# ESP32-P4 register map
Vendor: ESPRESSIF SYSTEMS (SHANGHAI) CO., LTD.; Series: ESP32 P-Series; File version: 3
CPU: RV32IMAFC r0p0, little endian, no MPU, FPU, 0 interrupt priority bits
Address unit: 32 bits
Registers are 32-bit, read-write, reset 0x0 unless marked. A register's access mark holds for its fields unless they carry their own. Offsets are from the block's base; [hi:lo] are bit positions; {n}, {i} and the like mark numbered series; <NAME> marks a mode.

## ISP (part 2 of 2) — ISP Peripheral
Base 0x500A1000
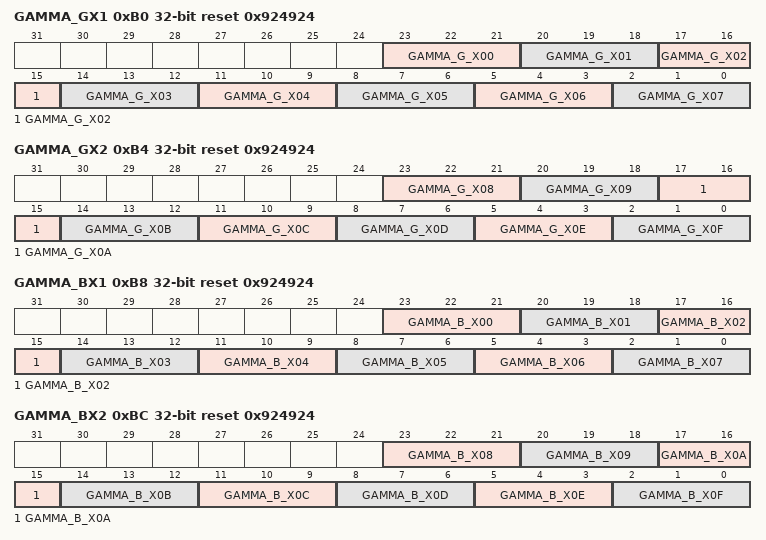
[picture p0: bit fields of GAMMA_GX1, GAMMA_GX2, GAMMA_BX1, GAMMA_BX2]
0xB0 GAMMA_GX1 reset 0x924924 — point of X-axis of g channel gamma curve register 1
  [23-3n:21-3n] GAMMA_G_X{n:02} (n=0..7) — this field configures the point {n} of X-axis of g channel gamma curve, it represents the power of the distance from the previous point
0xB4 GAMMA_GX2 reset 0x924924 — point of X-axis of g channel gamma curve register 2
  [23:21] GAMMA_G_X08 — this field configures the point 8 of X-axis of g channel gamma curve, it represents the power of the distance from the previous point
  [20:18] GAMMA_G_X09 — this field configures the point 9 of X-axis of g channel gamma curve, it represents the power of the distance from the previous point
  [17:15] GAMMA_G_X0A — this field configures the point 10 of X-axis of g channel gamma curve, it represents the power of the distance from the previous point
  [14:12] GAMMA_G_X0B — this field configures the point 11 of X-axis of g channel gamma curve, it represents the power of the distance from the previous point
  [11:9] GAMMA_G_X0C — this field configures the point 12 of X-axis of g channel gamma curve, it represents the power of the distance from the previous point
  [8:6] GAMMA_G_X0D — this field configures the point 13 of X-axis of g channel gamma curve, it represents the power of the distance from the previous point
  [5:3] GAMMA_G_X0E — this field configures the point 14 of X-axis of g channel gamma curve, it represents the power of the distance from the previous point
  [2:0] GAMMA_G_X0F — this field configures the point 15 of X-axis of g channel gamma curve, it represents the power of the distance from the previous point
0xB8 GAMMA_BX1 reset 0x924924 — point of X-axis of b channel gamma curve register 1
  [23-3n:21-3n] GAMMA_B_X{n:02} (n=0..7) — this field configures the point {n} of X-axis of b channel gamma curve, it represents the power of the distance from the previous point
0xBC GAMMA_BX2 reset 0x924924 — point of X-axis of b channel gamma curve register 2
  [23:21] GAMMA_B_X08 — this field configures the point 8 of X-axis of b channel gamma curve, it represents the power of the distance from the previous point
  [20:18] GAMMA_B_X09 — this field configures the point 9 of X-axis of b channel gamma curve, it represents the power of the distance from the previous point
  [17:15] GAMMA_B_X0A — this field configures the point 10 of X-axis of b channel gamma curve, it represents the power of the distance from the previous point
  [14:12] GAMMA_B_X0B — this field configures the point 11 of X-axis of b channel gamma curve, it represents the power of the distance from the previous point
  [11:9] GAMMA_B_X0C — this field configures the point 12 of X-axis of b channel gamma curve, it represents the power of the distance from the previous point
  [8:6] GAMMA_B_X0D — this field configures the point 13 of X-axis of b channel gamma curve, it represents the power of the distance from the previous point
  [5:3] GAMMA_B_X0E — this field configures the point 14 of X-axis of b channel gamma curve, it represents the power of the distance from the previous point
  [2:0] GAMMA_B_X0F — this field configures the point 15 of X-axis of b channel gamma curve, it represents the power of the distance from the previous point
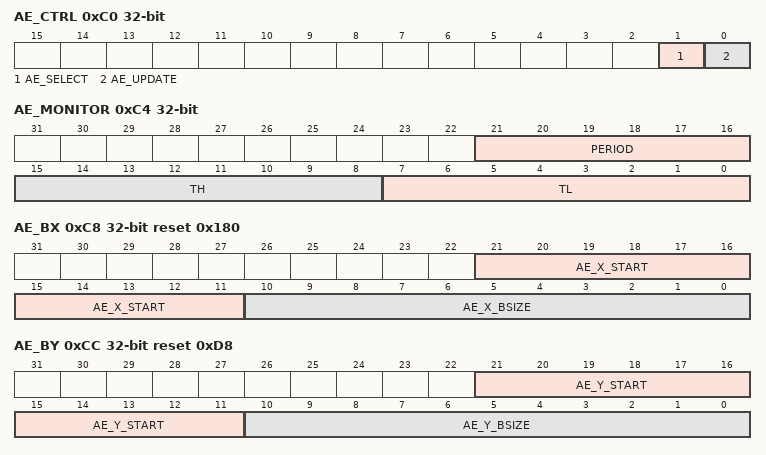
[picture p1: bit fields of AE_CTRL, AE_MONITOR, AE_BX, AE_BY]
0xC0 AE_CTRL access per field — ae control register
  [1] AE_SELECT rw — this field configures ae input data source, 0: data from median, 1: data from gama
  [0] AE_UPDATE wo — write 1 to this bit triggers one statistic event
0xC4 AE_MONITOR — ae monitor control register
  [21:16] PERIOD — this field cnfigures ae monitor frame period
  [15:8] TH — this field configures the higher lum threshold of ae monitor
  [7:0] TL — this field configures the lower lum threshold of ae monitor
0xC8 AE_BX reset 0x180 — ae window register in x-direction
  [21:11] AE_X_START — this field configures first block start x address
  [10:0] AE_X_BSIZE — this field configures every block x size
0xCC AE_BY reset 0xD8 — ae window register in y-direction
  [21:11] AE_Y_START — this field configures first block start y address
  [10:0] AE_Y_BSIZE — this field configures every block y size
0xD0 AE_WINPIXNUM reset 0x14400 — ae sub-window pix num register
  [16:0] AE_SUBWIN_PIXNUM — this field configures the pixel number of each sub win
0xD4 AE_WIN_RECIPROCAL — reciprocal of ae sub-window pixel number
  [19:0] AE_SUBWIN_RECIP — this field configures the reciprocal of each subwin_pixnum, 20bit fraction
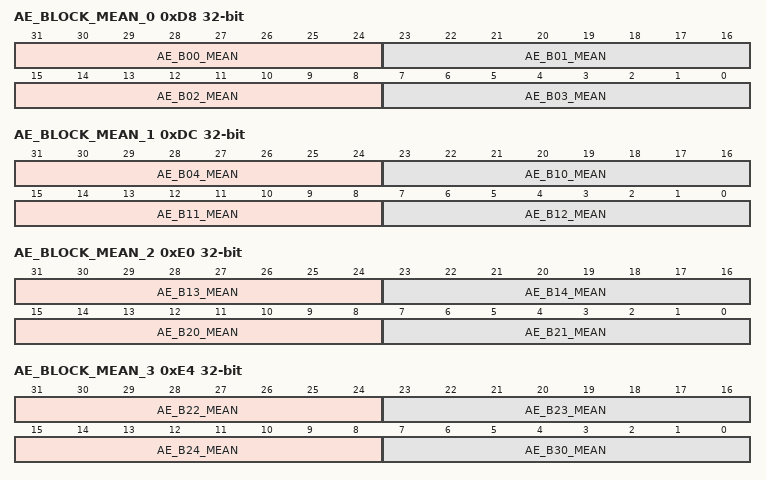
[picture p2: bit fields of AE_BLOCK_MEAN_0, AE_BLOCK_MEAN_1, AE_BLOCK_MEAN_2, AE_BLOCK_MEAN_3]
0xD8 AE_BLOCK_MEAN_0 ro — ae statistic result register 0
  [31-8n:24-8n] AE_B{n:02}_MEAN (n=0..3) — this field configures block{n:02} Y mean data
0xDC AE_BLOCK_MEAN_1 ro — ae statistic result register 1
  [31:24] AE_B04_MEAN — this field configures block04 Y mean data
  [23:16] AE_B10_MEAN — this field configures block10 Y mean data
  [15:8] AE_B11_MEAN — this field configures block11 Y mean data
  [7:0] AE_B12_MEAN — this field configures block12 Y mean data
0xE0 AE_BLOCK_MEAN_2 ro — ae statistic result register 2
  [31:24] AE_B13_MEAN — this field configures block13 Y mean data
  [23:16] AE_B14_MEAN — this field configures block14 Y mean data
  [15:8] AE_B20_MEAN — this field configures block20 Y mean data
  [7:0] AE_B21_MEAN — this field configures block21 Y mean data
0xE4 AE_BLOCK_MEAN_3 ro — ae statistic result register 3
  [31:24] AE_B22_MEAN — this field configures block22 Y mean data
  [23:16] AE_B23_MEAN — this field configures block23 Y mean data
  [15:8] AE_B24_MEAN — this field configures block24 Y mean data
  [7:0] AE_B30_MEAN — this field configures block30 Y mean data
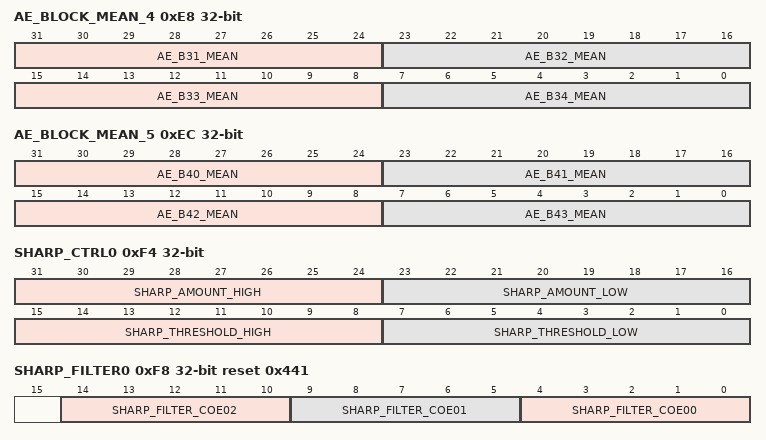
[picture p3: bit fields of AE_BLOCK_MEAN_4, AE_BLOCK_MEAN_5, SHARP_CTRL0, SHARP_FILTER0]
0xE8 AE_BLOCK_MEAN_4 ro — ae statistic result register 4
  [279-8n:272-8n] AE_B{n}_MEAN (n=31..34) — this field configures block{n} Y mean data
0xEC AE_BLOCK_MEAN_5 ro — ae statistic result register 5
  [351-8n:344-8n] AE_B{n}_MEAN (n=40..43) — this field configures block{n} Y mean data
0xF0 AE_BLOCK_MEAN_6 ro — ae statistic result register 6
  [31:24] AE_B44_MEAN — this field configures block44 Y mean data
0xF4 SHARP_CTRL0 — sharp control register 0
  [31:24] SHARP_AMOUNT_HIGH — this field configures sharpen amount for edge
  [23:16] SHARP_AMOUNT_LOW — this field configures sharpen amount for detail
  [15:8] SHARP_THRESHOLD_HIGH — this field configures sharpen threshold for edge
  [7:0] SHARP_THRESHOLD_LOW — this field configures sharpen threshold for detail
0xF8 SHARP_FILTER0 reset 0x441 — sharp usm config register 0
  [14:10] SHARP_FILTER_COE02 — this field configures usm filter coefficient
  [9:5] SHARP_FILTER_COE01 — this field configures usm filter coefficient
  [4:0] SHARP_FILTER_COE00 — this field configures unsharp masking(usm) filter coefficient
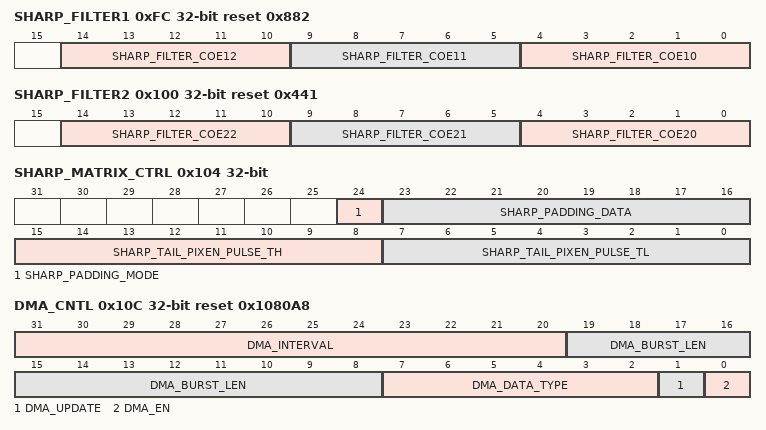
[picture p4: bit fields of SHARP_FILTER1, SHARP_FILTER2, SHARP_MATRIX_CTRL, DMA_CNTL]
0xFC SHARP_FILTER1 reset 0x882 — sharp usm config register 1
  [14:10] SHARP_FILTER_COE12 — this field configures usm filter coefficient
  [9:5] SHARP_FILTER_COE11 — this field configures usm filter coefficient
  [4:0] SHARP_FILTER_COE10 — this field configures usm filter coefficient
0x100 SHARP_FILTER2 reset 0x441 — sharp usm config register 2
  [14:10] SHARP_FILTER_COE22 — this field configures usm filter coefficient
  [9:5] SHARP_FILTER_COE21 — this field configures usm filter coefficient
  [4:0] SHARP_FILTER_COE20 — this field configures usm filter coefficient
0x104 SHARP_MATRIX_CTRL — sharp pix2matrix ctrl
  [24] SHARP_PADDING_MODE — this field configures sharp padding mode
  [23:16] SHARP_PADDING_DATA — this field configures sharp padding data
  [15:8] SHARP_TAIL_PIXEN_PULSE_TH — matrix tail pixen high level threshold, must < hnum-1, only reg_sharp_tail_pixen_pulse_th!=0 and reg_sharp_tail_pixen_pulse_tl!=0 and reg_sharp_tail_pixen_pulse_th < reg_sharp_tail_pixen_pulse_tl will enable tail pulse function
  [7:0] SHARP_TAIL_PIXEN_PULSE_TL — matrix tail pixen low level threshold, should not to large to prevent expanding to next frame, only reg_demosaic_tail_pixen_pulse_th!=0 and reg_demosaic_tail_pixen_pulse_tl!=0 and reg_demosaic_tail_pixen_pulse_th < reg_demosaic_tail_pixen_pulse_tl will enable tail pulse function
0x108 SHARP_CTRL1 ro — sharp control register 1
  [7:0] SHARP_GRADIENT_MAX — this field configures sharp max gradient, refresh at the end of each frame end
0x10C DMA_CNTL access per field reset 0x1080A8 — isp dma source trans control register
  [31:20] DMA_INTERVAL rw — this field configures dma req interval, 12'b1: 1 cycle, 12'b11 2 cycle ...
  [19:8] DMA_BURST_LEN rw — this field configures dma burst len when data source is dma. set according to dma_msize, it is the number of 64bits in a dma transfer
  [7:2] DMA_DATA_TYPE rw — this field configures the idi data type for image data
  [1] DMA_UPDATE rw — write 1 to update reg_dma_burst_len & reg_dma_data_type
  [0] DMA_EN wo — write 1 to triger dma to get 1 frame
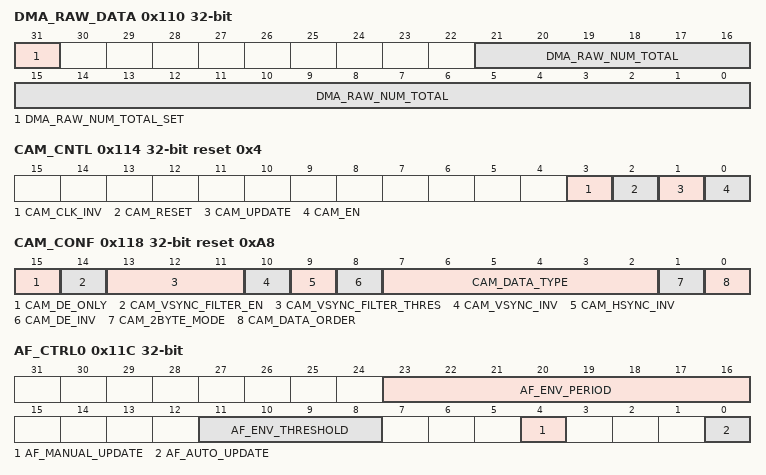
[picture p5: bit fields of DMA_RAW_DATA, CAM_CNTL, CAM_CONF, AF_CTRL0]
0x110 DMA_RAW_DATA access per field — isp dma source total raw number set register
  [31] DMA_RAW_NUM_TOTAL_SET wo — write 1 to update reg_dma_raw_num_total
  [21:0] DMA_RAW_NUM_TOTAL rw — this field configures the the number of 64bits in a frame
0x114 CAM_CNTL reset 0x4 — isp cam source control register
  [3] CAM_CLK_INV — this bit configures the invertion of cam clk from pad. 0: not invert cam clk, 1: invert cam clk
  [2] CAM_RESET — this bit configures cam clk domain reset, 1: reset cam input logic, 0: release reset
  [1] CAM_UPDATE — write 1 to update ISP_CAM_CONF
  [0] CAM_EN — write 1 to start recive camera data, write 0 to disable
0x118 CAM_CONF reset 0xA8 — isp cam source config register
  [15] CAM_DE_ONLY — configures whether cam inf only has de, no hsync data. 0: has hsync, 1: no hsync
  [14] CAM_VSYNC_FILTER_EN — this bit configures vsync filter en
  [13:11] CAM_VSYNC_FILTER_THRES — this bit configures the number of clock of vsync filter length
  [10] CAM_VSYNC_INV — this bit configures cam vsync invert. 0: not invert, 1: invert
  [9] CAM_HSYNC_INV — this bit configures cam hsync invert. 0: not invert, 1: invert
  [8] CAM_DE_INV — this bit configures cam data enable invert. 0: not invert, 1: invert
  [7:2] CAM_DATA_TYPE — this field configures idi data type for image data, 0x2a: RAW8, 0x2b: RAW10, 0x2c: RAW12
  [1] CAM_2BYTE_MODE — this field configures enable of cam 2 byte mode(input 2 bytes each clock). 0: disable, 1: enable
  [0] CAM_DATA_ORDER — this field configures data order of cam port, 0: cam_data_in, 1:{cam_data_in[7:0], cam_data_in[15:8]}
0x11C AF_CTRL0 access per field — af control register 0
  [23:16] AF_ENV_PERIOD rw — this field configures environment changes detection period (frame). When set to 0, disable this function
  [11:8] AF_ENV_THRESHOLD rw — this field configures env threshold. when both sum and lum changes larger than this value, consider environment changes and need to trigger a new autofocus. 4Bit fractional
  [4] AF_MANUAL_UPDATE wo — write 1 to this bit will update the sum and lum once
  [0] AF_AUTO_UPDATE rw — this bit configures auto_update enable. when set to 1, will update sum and lum each frame
0x120 AF_CTRL1 — af control register 1
  [21:0] AF_THPIXNUM — this field configures pixnum used when calculating the autofocus threshold. Set to 0 to disable threshold calculation
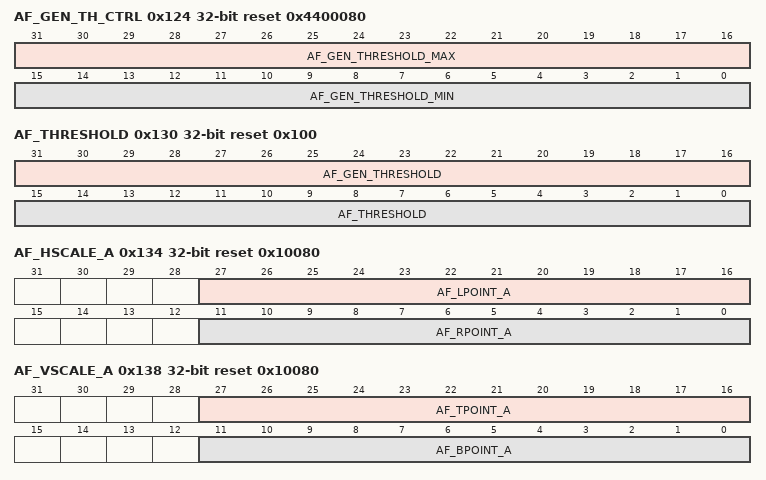
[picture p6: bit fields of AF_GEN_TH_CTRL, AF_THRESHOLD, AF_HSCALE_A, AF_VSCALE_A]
0x124 AF_GEN_TH_CTRL reset 0x4400080 — af gen threshold control register
  [31:16] AF_GEN_THRESHOLD_MAX — this field configures max threshold when use auto_threshold
  [15:0] AF_GEN_THRESHOLD_MIN — this field configures min threshold when use auto_threshold
0x128 AF_ENV_USER_TH_SUM — af monitor user sum threshold register
  [31:0] AF_ENV_USER_THRESHOLD_SUM — this field configures user setup env detect sum threshold
0x12C AF_ENV_USER_TH_LUM — af monitor user lum threshold register
  [29:0] AF_ENV_USER_THRESHOLD_LUM — this field configures user setup env detect lum threshold
0x130 AF_THRESHOLD access per field reset 0x100
  [31:16] AF_GEN_THRESHOLD ro — this field represents the last calculated threshold
  [15:0] AF_THRESHOLD rw — this field configures user threshold. When set to non-zero, autofocus will use this threshold
0x134 AF_HSCALE_A reset 0x10080 — h-scale of af window a register
  [27:16] AF_LPOINT_A — this field configures top coordinate of focus window a, must >= 2
  [11:0] AF_RPOINT_A — this field configures left coordinate of focus window a, must >= 2
0x138 AF_VSCALE_A reset 0x10080 — v-scale of af window a register
  [27:16] AF_TPOINT_A — this field configures bottom coordinate of focus window a, must <= hnum-2
  [11:0] AF_BPOINT_A — this field configures right coordinate of focus window a, must <= hnum-2
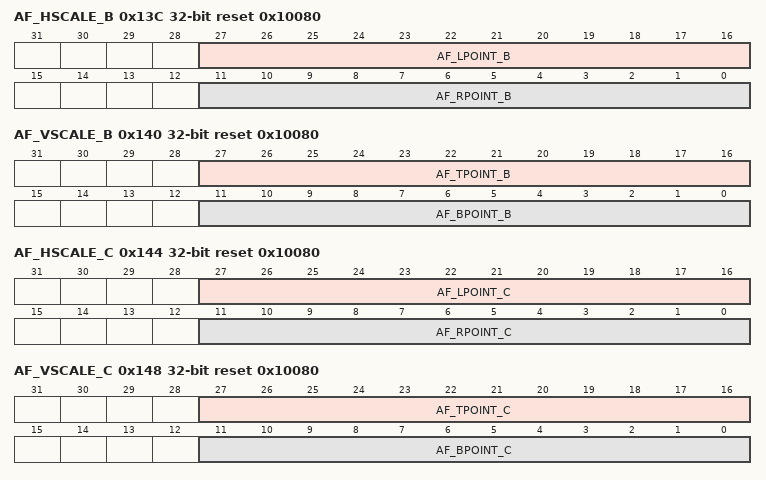
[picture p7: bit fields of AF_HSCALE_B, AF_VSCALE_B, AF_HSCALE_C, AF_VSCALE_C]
0x13C AF_HSCALE_B reset 0x10080 — h-scale of af window b register
  [27:16] AF_LPOINT_B — this field configures top coordinate of focus window b, must >= 2
  [11:0] AF_RPOINT_B — this field configures left coordinate of focus window b, must >= 2
0x140 AF_VSCALE_B reset 0x10080 — v-scale of af window b register
  [27:16] AF_TPOINT_B — this field configures bottom coordinate of focus window b, must <= hnum-2
  [11:0] AF_BPOINT_B — this field configures right coordinate of focus window b, must <= hnum-2
0x144 AF_HSCALE_C reset 0x10080 — v-scale of af window c register
  [27:16] AF_LPOINT_C — this field configures top coordinate of focus window c, must >= 2
  [11:0] AF_RPOINT_C — this field configures left coordinate of focus window c, must >= 2
0x148 AF_VSCALE_C reset 0x10080 — v-scale of af window c register
  [27:16] AF_TPOINT_C — this field configures bottom coordinate of focus window c, must <= hnum-2
  [11:0] AF_BPOINT_C — this field configures right coordinate of focus window c, must <= hnum-2
0x14C AF_SUM_A ro — result of sum of af window a
  [29:0] AF_SUMA — this field represents the result of accumulation of pix grad of focus window a
0x150 AF_SUM_B ro — result of sum of af window b
  [29:0] AF_SUMB — this field represents the result of accumulation of pix grad of focus window b
0x154 AF_SUM_C ro — result of sum of af window c
  [29:0] AF_SUMC — this field represents the result of accumulation of pix grad of focus window c
0x158 AF_LUM_A ro — result of lum of af window a
  [27:0] AF_LUMA — this field represents the result of accumulation of pix light of focus window a
0x15C AF_LUM_B ro — result of lum of af window b
  [27:0] AF_LUMB — this field represents the result of accumulation of pix light of focus window b
0x160 AF_LUM_C ro — result of lum of af window c
  [27:0] AF_LUMC — this field represents the result of accumulation of pix light of focus window c
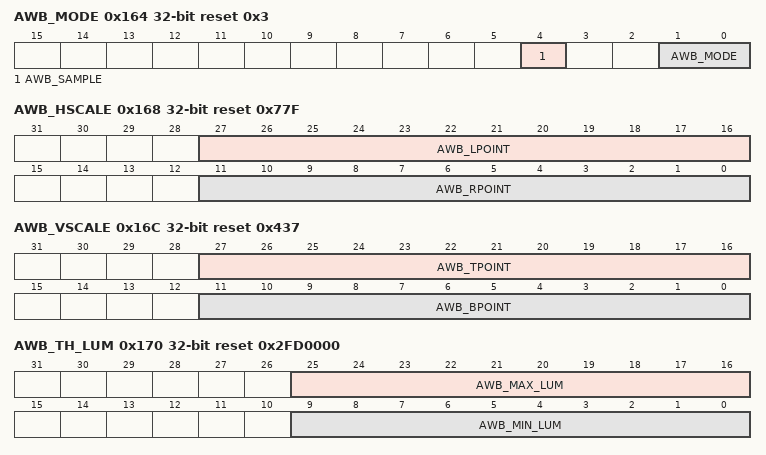
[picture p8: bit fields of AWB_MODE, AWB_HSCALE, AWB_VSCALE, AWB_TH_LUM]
0x164 AWB_MODE reset 0x3 — awb mode control register
  [4] AWB_SAMPLE — this bit configures awb sample location, 0:before ccm, 1:after ccm
  [1:0] AWB_MODE — this field configures awb algo sel. 00: none sellected. 01: sel algo0. 10: sel algo1. 11: sel both algo0 and algo1
0x168 AWB_HSCALE reset 0x77F — h-scale of awb window
  [27:16] AWB_LPOINT — this field configures awb window left coordinate
  [11:0] AWB_RPOINT — this field configures awb window right coordinate
0x16C AWB_VSCALE reset 0x437 — v-scale of awb window
  [27:16] AWB_TPOINT — this field configures awb window top coordinate
  [11:0] AWB_BPOINT — this field configures awb window bottom coordinate
0x170 AWB_TH_LUM reset 0x2FD0000 — awb lum threshold register
  [25:16] AWB_MAX_LUM — this field configures upper threshold of r+g+b
  [9:0] AWB_MIN_LUM — this field configures lower threshold of r+g+b
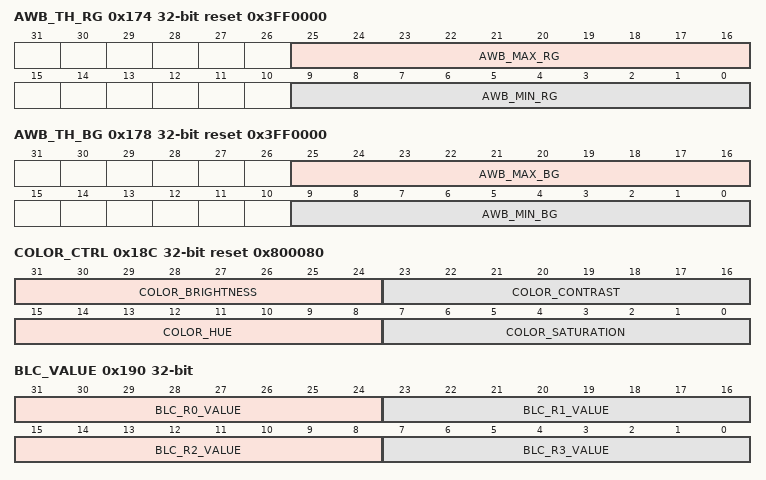
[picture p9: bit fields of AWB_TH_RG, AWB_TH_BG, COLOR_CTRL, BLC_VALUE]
0x174 AWB_TH_RG reset 0x3FF0000 — awb r/g threshold register
  [25:16] AWB_MAX_RG — this field configures upper threshold of r/g, 2bit integer and 8bit fraction
  [9:0] AWB_MIN_RG — this field configures lower threshold of r/g, 2bit integer and 8bit fraction
0x178 AWB_TH_BG reset 0x3FF0000 — awb b/g threshold register
  [25:16] AWB_MAX_BG — this field configures upper threshold of b/g, 2bit integer and 8bit fraction
  [9:0] AWB_MIN_BG — this field configures lower threshold of b/g, 2bit integer and 8bit fraction
0x17C AWB0_WHITE_CNT ro — result of awb white point number
  [23:0] AWB0_WHITE_CNT — this field configures number of white point detected of algo0
0x180 AWB0_ACC_R ro — result of accumulate of r channel of all white points
  [31:0] AWB0_ACC_R — this field represents accumulate of channel r of all white point of algo0
0x184 AWB0_ACC_G ro — result of accumulate of g channel of all white points
  [31:0] AWB0_ACC_G — this field represents accumulate of channel g of all white point of algo0
0x188 AWB0_ACC_B ro — result of accumulate of b channel of all white points
  [31:0] AWB0_ACC_B — this field represents accumulate of channel b of all white point of algo0
0x18C COLOR_CTRL reset 0x800080 — color control register
  [31:24] COLOR_BRIGHTNESS — this field configures the color brightness value, signed 2's complement
  [23:16] COLOR_CONTRAST — this field configures the color contrast value
  [15:8] COLOR_HUE — this field configures the color hue angle
  [7:0] COLOR_SATURATION — this field configures the color saturation value
0x190 BLC_VALUE — blc black level register
  [31:24] BLC_R0_VALUE — this field configures the black level of top left channel of bayer img
  [23:16] BLC_R1_VALUE — this field configures the black level of top right channel of bayer img
  [15:8] BLC_R2_VALUE — this field configures the black level of bottom left channel of bayer img
  [7:0] BLC_R3_VALUE — this field configures the black level of bottom right channel of bayer img
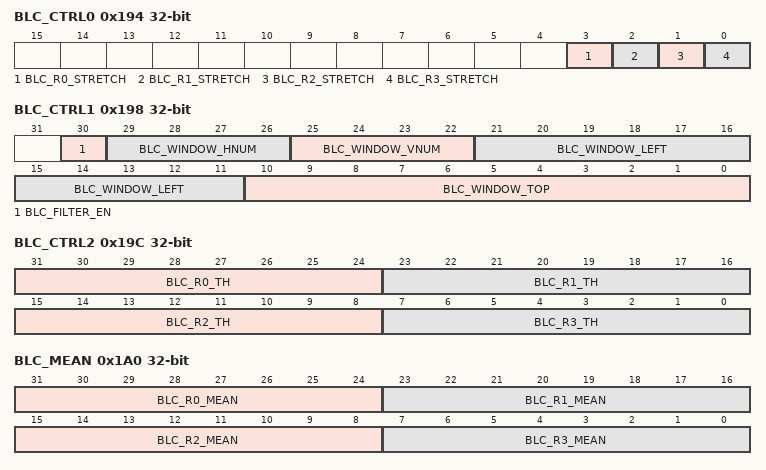
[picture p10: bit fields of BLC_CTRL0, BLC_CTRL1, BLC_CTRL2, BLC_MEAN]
0x194 BLC_CTRL0 — blc stretch control register
  [3] BLC_R0_STRETCH — this bit configures the stretch feature of top left channel. 0: stretch disable, 1: stretch enable
  [2] BLC_R1_STRETCH — this bit configures the stretch feature of top right channel. 0: stretch disable, 1: stretch enable
  [1] BLC_R2_STRETCH — this bit configures the stretch feature of bottom left channel. 0: stretch disable, 1: stretch enable
  [0] BLC_R3_STRETCH — this bit configures the stretch feature of bottom right channel. 0: stretch disable, 1: stretch enable
0x198 BLC_CTRL1 — blc window control register
  [30] BLC_FILTER_EN — this bit configures enable blc average input filter. 0: disable, 1: enable
  [29:26] BLC_WINDOW_HNUM — this field configures blc average calculation window hnum
  [25:22] BLC_WINDOW_VNUM — this field configures blc average calculation window vnum
  [21:11] BLC_WINDOW_LEFT — this field configures blc average calculation window left
  [10:0] BLC_WINDOW_TOP — this field configures blc average calculation window top
0x19C BLC_CTRL2 — blc black threshold control register
  [31:24] BLC_R0_TH — this field configures black threshold when get blc average of top left channel
  [23:16] BLC_R1_TH — this field configures black threshold when get blc average of top right channel
  [15:8] BLC_R2_TH — this field configures black threshold when get blc average of bottom left channel
  [7:0] BLC_R3_TH — this field configures black threshold when get blc average of bottom right channel
0x1A0 BLC_MEAN ro — results of the average of black window
  [31:24] BLC_R0_MEAN — this field represents the average black value of top left channel
  [23:16] BLC_R1_MEAN — this field represents the average black value of top right channel
  [15:8] BLC_R2_MEAN — this field represents the average black value of bottom left channel
  [7:0] BLC_R3_MEAN — this field represents the average black value of bottom right channel
0x1A4 HIST_MODE reset 0x4 — histogram mode control register
  [2:0] HIST_MODE — this field configures statistic mode. 0: RAW_B, 1: RAW_GB, 2: RAW_GR 3: RAW_R, 4: RGB, 5:YUV_Y, 6:YUV_U, 7:YUV_V
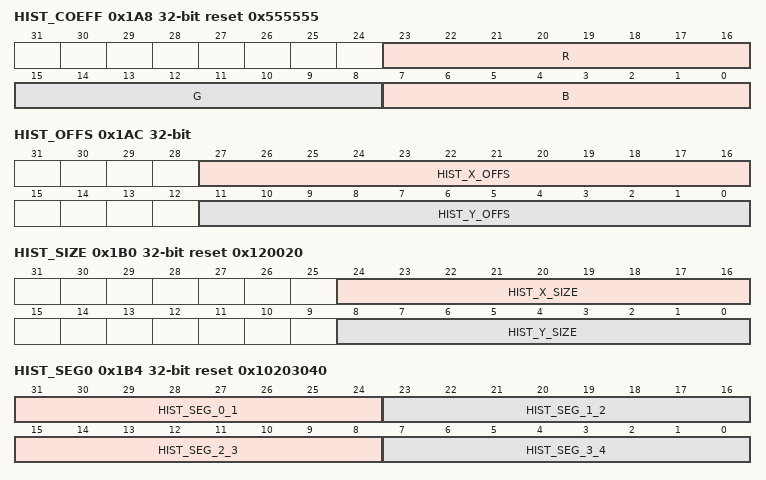
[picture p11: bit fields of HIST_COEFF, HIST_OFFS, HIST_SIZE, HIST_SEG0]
0x1A8 HIST_COEFF reset 0x555555 — histogram rgb to gray coefficients register
  [23:16] R — this field configures coefficient of R when set hist_mode to RGB, sum of coeff_r and coeff_g and coeff_b should be 256
  [15:8] G — this field configures coefficient of G when set hist_mode to RGB, sum of coeff_r and coeff_g and coeff_b should be 256
  [7:0] B — this field configures coefficient of B when set hist_mode to RGB, sum of coeff_r and coeff_g and coeff_b should be 256
0x1AC HIST_OFFS — histogram window offsets register
  [27:16] HIST_X_OFFS — this field configures x coordinate of first window
  [11:0] HIST_Y_OFFS — this field configures y coordinate of first window
0x1B0 HIST_SIZE reset 0x120020 — histogram sub-window size register
  [24:16] HIST_X_SIZE — this field configures x direction size of subwindow
  [8:0] HIST_Y_SIZE — this field configures y direction size of subwindow
0x1B4 HIST_SEG0 reset 0x10203040 — histogram bin control register 0
  [31-8n:24-8n] HIST_SEG_{n}_{n+1} (n=0..3) — this field configures threshold of histogram bin {n} and bin {n+1}
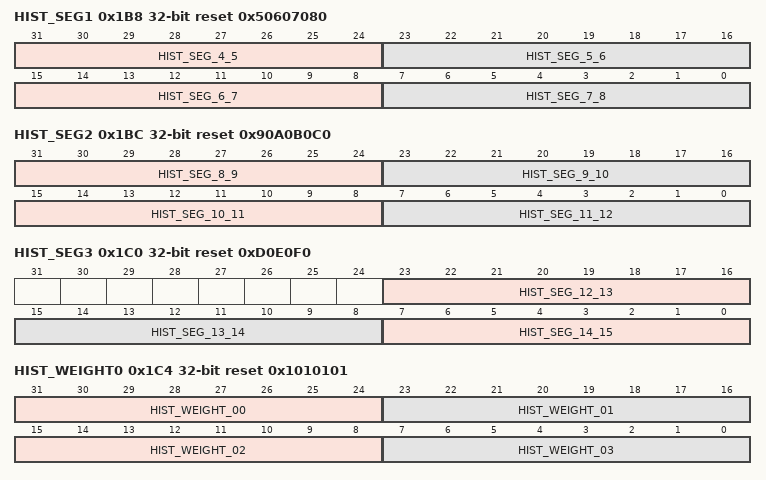
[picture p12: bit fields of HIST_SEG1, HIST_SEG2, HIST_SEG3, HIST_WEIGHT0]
0x1B8 HIST_SEG1 reset 0x50607080 — histogram bin control register 1
  [63-8n:56-8n] HIST_SEG_{n}_{n+1} (n=4..7) — this field configures threshold of histogram bin {n} and bin {n+1}
0x1BC HIST_SEG2 reset 0x90A0B0C0 — histogram bin control register 2
  [95-8n:88-8n] HIST_SEG_{n}_{n+1} (n=8..11) — this field configures threshold of histogram bin {n} and bin {n+1}
0x1C0 HIST_SEG3 reset 0xD0E0F0 — histogram bin control register 3
  [23:16] HIST_SEG_12_13 — this field configures threshold of histogram bin 12 and bin 13
  [15:8] HIST_SEG_13_14 — this field configures threshold of histogram bin 13 and bin 14
  [7:0] HIST_SEG_14_15 — this field configures threshold of histogram bin 14 and bin 15
0x1C4 HIST_WEIGHT0 reset 0x1010101 — histogram sub-window weight register 0
  [31:24] HIST_WEIGHT_00 — this field configures weight of subwindow 00 and sum of all weight should be 256
  [23:16] HIST_WEIGHT_01 — this field configures weight of subwindow 01
  [15:8] HIST_WEIGHT_02 — this field configures weight of subwindow 02
  [7:0] HIST_WEIGHT_03 — this field configures weight of subwindow 03
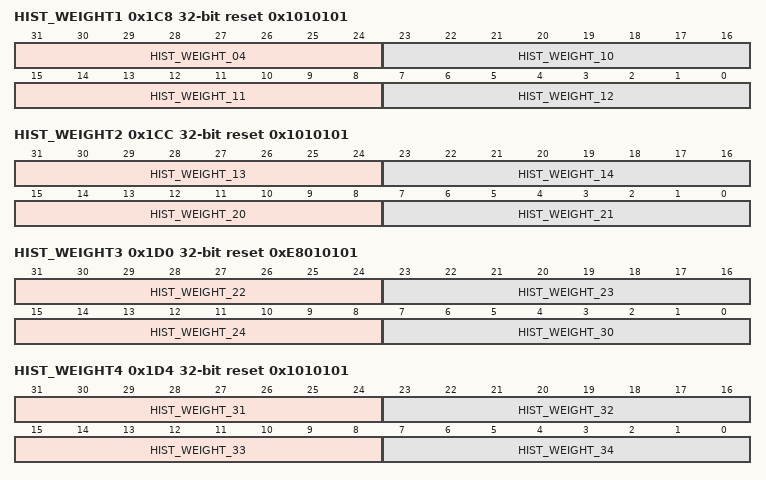
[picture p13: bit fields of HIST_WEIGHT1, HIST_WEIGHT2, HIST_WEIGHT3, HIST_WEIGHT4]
0x1C8 HIST_WEIGHT1 reset 0x1010101 — histogram sub-window weight register 1
  [31:24] HIST_WEIGHT_04 — this field configures weight of subwindow 04
  [23:16] HIST_WEIGHT_10 — this field configures weight of subwindow 10
  [15:8] HIST_WEIGHT_11 — this field configures weight of subwindow 11
  [7:0] HIST_WEIGHT_12 — this field configures weight of subwindow 12
0x1CC HIST_WEIGHT2 reset 0x1010101 — histogram sub-window weight register 2
  [31:24] HIST_WEIGHT_13 — this field configures weight of subwindow 13
  [23:16] HIST_WEIGHT_14 — this field configures weight of subwindow 04
  [15:8] HIST_WEIGHT_20 — this field configures weight of subwindow 20
  [7:0] HIST_WEIGHT_21 — this field configures weight of subwindow 21
0x1D0 HIST_WEIGHT3 reset 0xE8010101 — histogram sub-window weight register 3
  [31:24] HIST_WEIGHT_22 — this field configures weight of subwindow 22
  [23:16] HIST_WEIGHT_23 — this field configures weight of subwindow 23
  [15:8] HIST_WEIGHT_24 — this field configures weight of subwindow 24
  [7:0] HIST_WEIGHT_30 — this field configures weight of subwindow 30
0x1D4 HIST_WEIGHT4 reset 0x1010101 — histogram sub-window weight register 4
  [279-8n:272-8n] HIST_WEIGHT_{n} (n=31..34) — this field configures weight of subwindow {n}
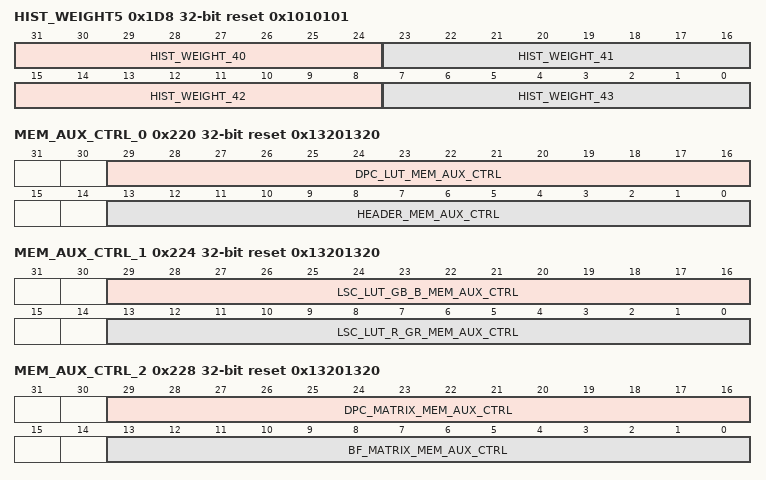
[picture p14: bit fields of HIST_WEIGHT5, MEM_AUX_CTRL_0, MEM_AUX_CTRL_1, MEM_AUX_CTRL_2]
0x1D8 HIST_WEIGHT5 reset 0x1010101 — histogram sub-window weight register 5
  [351-8n:344-8n] HIST_WEIGHT_{n} (n=40..43) — this field configures weight of subwindow {n}
0x1DC HIST_WEIGHT6 reset 0x1 — histogram sub-window weight register 6
  [7:0] HIST_WEIGHT_44 — this field configures weight of subwindow 44
{0x1E0+4i} HIST_BIN{i} ro (i=0..15) — result of histogram bin {i}
  [16:0] HIST_BIN_{i} — this field represents result of histogram bin {i}
0x220 MEM_AUX_CTRL_0 reset 0x13201320 — mem aux control register 0
  [29:16] DPC_LUT_MEM_AUX_CTRL — this field represents this field configures the mem_aux of dpc lut memory
  [13:0] HEADER_MEM_AUX_CTRL — this field configures the mem_aux of isp input buffer memory
0x224 MEM_AUX_CTRL_1 reset 0x13201320 — mem aux control register 1
  [29:16] LSC_LUT_GB_B_MEM_AUX_CTRL — this field configures the mem_aux of lsc gb b lut memory
  [13:0] LSC_LUT_R_GR_MEM_AUX_CTRL — this field configures the mem_aux of lsc r gr lut memory
0x228 MEM_AUX_CTRL_2 reset 0x13201320 — mem aux control register 2
  [29:16] DPC_MATRIX_MEM_AUX_CTRL — this field configures the mem_aux of dpc line buffer memory
  [13:0] BF_MATRIX_MEM_AUX_CTRL — this field configures the mem_aux of bf line buffer memory
0x22C MEM_AUX_CTRL_3 reset 0x13201320 — mem aux control register 3
  [29:16] DEMOSAIC_MATRIX_MEM_AUX_CTRL — this field configures the mem_aux of demosaic line buffer memory
  [13:0] SHARP_MATRIX_Y_MEM_AUX_CTRL — this field configures the mem_aux of sharp y line buffer memory
0x230 MEM_AUX_CTRL_4 reset 0x1320 — mem aux control register 4
  [13:0] SHARP_MATRIX_UV_MEM_AUX_CTRL — this field configures the mem_aux of sharp uv line buffer memory
0x234 YUV_FORMAT — yuv format control register
  [1] YUV_RANGE — this bit configures the yuv range. 0: full range, 1: limit range
  [0] YUV_MODE — this bit configures the yuv mode. 0: ITU-R BT.601, 1: ITU-R BT.709
0x238 RDN_ECO_CS access per field
  [1] RDN_ECO_RESULT ro, [0] RDN_ECO_EN rw
0x23C RDN_ECO_LOW — rdn eco all low register
0x240 RDN_ECO_HIGH reset 0xFFFFFFFF — rdn eco all high register
0x244 CROP_CTRL wo — isp_crop ctrl register
  [0] CROP_SFT_RST — Write 1 to clear err st
0x248 CROP_Y_CAPTURE — isp_crop row capture range register
  [23:12] CROP_Y_END — isp_crop capture row end index
  [11:0] CROP_Y_START — isp_crop capture row start index
0x24C CROP_X_CAPTURE — isp_crop col capture range register
  [23:12] CROP_X_END — isp_crop capture col end index
  [11:0] CROP_X_START — isp_crop capture col start index
0x250 CROP_ERR_ST ro — crop error state register
  [5] CROP_X_START_ODD — Represents isp_corp col start index is an odd number
  [4] CROP_Y_START_ODD — Represents isp_corp row start index is an odd number
  [3] CROP_X_END_EVEN — Represents isp_corp col end index is an even number
  [2] CROP_Y_END_EVEN — Represents isp_corp row end index is an even number
  [1] CROP_X_MISMATCH — Represents isp_corp col end index over image size
  [0] CROP_Y_MISMATCH — Represents isp_corp row end index over image size
0x254 WBG_COEF_R reset 0x100 — white balance red gain register 0
  [11:0] WBG_R — Configures the white balance red gain
0x258 WBG_COEF_G reset 0x100 — white balance green gain register 0
  [11:0] WBG_G — Configures the white balance green gain
0x25C WBG_COEF_B reset 0x100 — white balance blue gain register 0
  [11:0] WBG_B — Configures the white balance blue gain
0x260 COLOR_HUE_CTRL — color control register
  [0] COLOR_HUE_H — Configures the color hue angle most bit
0x264 AWB_BX — awb window register in x-direction
  [23:12] AWB_X_START — Configures first block start x address
  [11:0] AWB_X_BSIZE — Configures every block x size, min number is 4
0x268 AWB_BY — awb window register in y-direction
  [23:12] AWB_Y_START — Configures first block start y address
  [11:0] AWB_Y_BSIZE — Configures every block y size
0x26C STATE ro — awb window register in y-direction
  [1] HEADER_BUSY — Represents isp_header state
  [0] TAIL_BUSY — Represents isp_tail state
0x270 SHADOW_REG_CTRL reset 0x40000000 — shadow register ctrl register
  [31:30] SHADOW_UPDATE_SEL — Configures shadow register update type. 0: no shadow register. 1: update every vsyn. 2: update only the next vsync after write reg_xxx_update
  [7] COLOR_UPDATE — Write 1 to update color configuration register
  [6] SHARP_UPDATE — Write 1 to update sharp configuration register
  [4] CCM_UPDATE — Write 1 to update ccm configuration register
  [3] WBG_UPDATE — Write 1 to update wbg configuration register
  [2] BF_UPDATE — Write 1 to update bf configuration register
  [1] DPC_UPDATE — Write 1 to update dpc configuration register
  [0] BLC_UPDATE — Write 1 to update blc configuration register
